# M451_v1 register map
File version: 1.0
Registers are 32-bit, read-write, reset 0x0 unless marked. A register's access mark holds for its fields unless they carry their own. Offsets are from the block's base; [hi:lo] are bit positions; {n}, {i} and the like mark numbered series; 'fields as' and 'values as' point back to an identical list.

## I2C0 — I2C Register Map
Base 0x40080000
Same registers: I2C1 0x40081000
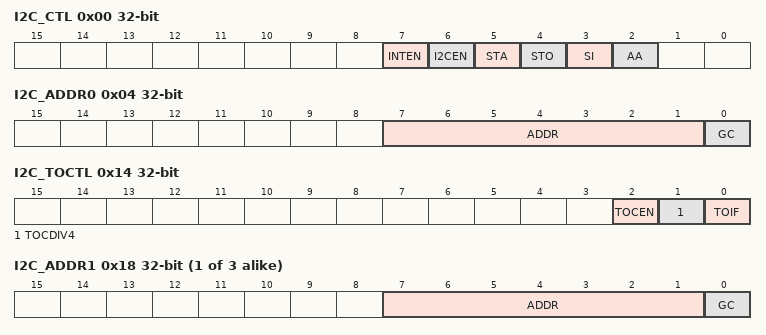
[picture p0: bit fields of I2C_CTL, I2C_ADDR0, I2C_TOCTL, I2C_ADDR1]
0x00 I2C_CTL — I2C Control Register
  [7] INTEN — Enable Interrupt
    0=I2C interrupt Disabled; 1=I2C interrupt Enabled
  [6] I2CEN — I2C Controller Enable Bit
    0=I2C Controller Disabled; 1=I2C Controller Enabled
  [5] STA — I2C START Control. Setting STA to logic 1 to enter Master mode, the I2C hardware sends a START or repeat START condition to bus when the bus is free.
  [4] STO — I2C STOP Control. In Master mode, setting STO to transmit a STOP condition to bus then I2C controller will check the bus condition if a STOP condition is detected. This bit will be cleared by hardware automatically.
  [3] SI — I2C Interrupt Flag. When a new I2C state is present in the I2C_STATUS register, the SI flag is set by hardware. If bit INTEN (I2C_CTL [7]) is set, the I2C interrupt is requested. SI must be cleared by software. Clear SI by writing 1 to this bit. For ACKMEN is set in slave read mode, the SI flag is set in 8th clock period for user to confirm the acknowledge bit and 9th clock period for user to read the data in the data buffer.
  [2] AA — Assert Acknowledge Control
0x04 I2C_ADDR0 — I2C Slave Address Register0
  [7:1] ADDR — I2C Address. The content of this register is irrelevant when I2C is in Master mode. In the slave mode, the seven most significant bits must be loaded with the chip's own address. The I2C hardware will react if either of the address is matched.
  [0] GC — General Call Function
    0=General Call Function Disabled; 1=General Call Function Enabled
0x08 I2C_DAT — I2C Data Register
  [7:0] DAT — I2C Data. Bit [7:0] is located with the 8-bit transferred/received data of I2C serial port.
0x0C I2C_STATUS ro reset 0xF8
  [7:0] STATUS — I2C Status. 2. If the BUSEN and PECEN are enabled, the status of PECERR, I2C_BUSSTS[3], is used to substitute for I2C_STATUS to check the ACK status in the last frame when the byte count done interrupt has active and the PEC frame has been transformed.
0x10 I2C_CLKDIV — I2C Clock Divided Register
  [7:0] DIVIDER — I2C Clock Divided. Note: The minimum value of I2C_CLKDIV is 4.
0x14 I2C_TOCTL — I2C Time-out Control Register
  [2] TOCEN — Time-out Counter Enable Bit. When Enabled, the 14-bit time-out counter will start counting when SI is clear. Setting flag SI to '1' will reset counter and re-start up counting after SI is cleared.
    0=Time-Out Counter Disabled; 1=Time-Out Counter Enabled
  [1] TOCDIV4 — Time-out Counter Input Clock Divided by 4. When Enabled, The time-out period is extend 4 times.
    0=Time-Out Counter Input Clock Divided Disabled; 1=Time-Out Counter Input Clock Divided Enabled
  [0] TOIF — Time-out Flag. This bit is set by hardware when I2C time-out happened and it can interrupt CPU if I2C interrupt enable bit (INTEN) is set to 1. Note: Software can write 1 to clear this bit.
{0x14+4i} I2C_ADDR{i} (i=1..3) — I2C Slave Address Register{i}
  fields as I2C_ADDR0
{0x24+4i} I2C_ADDRMSK{i} (i=0..3) — I2C Slave Address Mask Register{i}
  [7:1] ADDRMSK — I2C Address Mask. I2C bus controllers support multiple address recognition with four address mask register. When the bit in the address mask register is set to one, it means the received corresponding address bit is don't-care. If the bit is set to zero, that means the received corresponding register bit should be exact the same as address register.
    0=Mask Disabled (the received corresponding register bit should be exact the same as address register.); 1=Mask Enabled (the received corresponding address bit is don't care.)
0x3C I2C_WKCTL — I2C Wake-up Control Register
  [0] WKEN — I2C Wake-up Enable Bit
    0=I2C wake-up function Disabled; 1=I2C wake-up function Enabled
0x40 I2C_WKSTS — I2C Wake-up Status Register
  [0] WKIF — I2C Wake-up Flag. When chip is woken up from Power-down mode by I2C, this bit is set to 1. Software can write 1 to clear this bit.
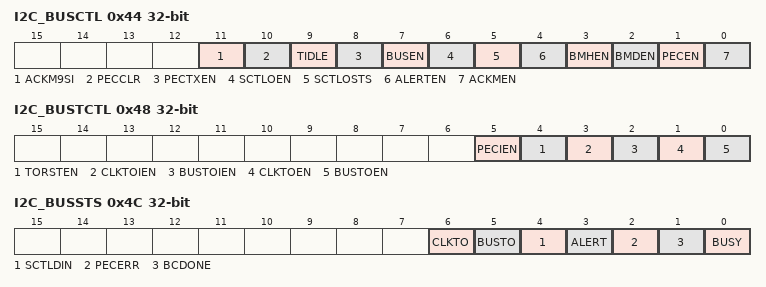
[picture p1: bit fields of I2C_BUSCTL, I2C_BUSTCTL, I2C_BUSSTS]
0x44 I2C_BUSCTL — I2C Bus Management Control Register
  [11] ACKM9SI — Acknowledge Manual Enable Extra SI Interrupt
    0=There is no SI interrupt in the 9th clock cycle when the BUSEN =1 and ACKMEN =1; 1=There is SI interrupt in the 9th clock cycle when the BUSEN =1 and ACKMEN =1
  [10] PECCLR — PEC Clear at Repeat Start. The calculation of PEC starts when PECEN is set to 1 and it is clear when the STA or STO bit is detected. This PECCLR bit is used to enable the condition of REPEAT START can clear the PEC calculation.
    0=The PEC calculation is cleared by 'Repeat Start' function is Disabled; 1=The PEC calculation is cleared by 'Repeat Start' function is Enabled
  [9] TIDLE — Timer Check in Idle State. The BUSTOUT is used to calculate the time-out of clock low in bus active and the idle period in bus Idle. This bit is used to define which condition is enabled. Note: The BUSY (I2C_BUSSTS[0]) indicate the current bus state.
    0=The BUSTOUT is used to calculate the clock low period in bus active; 1=The BUSTOUT is used to calculate the IDLE period in bus Idle
  [8] PECTXEN — Packet Error Checking Byte Transmission/Reception. This bit is set by software, and cleared by hardware when the PEC is transferred, or when a STOP condition or an Address Matched is received
    0=No PEC transfer; 1=PEC transmission/reception is requested
  [7] BUSEN — BUS Enable Bit. Note: When the bit is enabled, the internal 14-bit counter is used to calculate the time out event of clock low condition.
    0=The system management function is Disabled; 1=The system management function is Enable
  [6] SCTLOEN — Suspend or Control Pin Output Enable Bit
    0=The SUSCON pin in input; 1=The output enable is active on the SUSCON pin
  [5] SCTLOSTS — Suspend/Control Data Output Status
    0=The output of SUSCON pin is low; 1=The output of SUSCON pin is high
  [4] ALERTEN — Bus Management Alert Enable Bit
    0=Release the BM_ALERT pin high and Alert Response Header disabled: 0001100x followed by NACK if both of BMDEN and ACKMEN are enabled. BM_ALERT pin not supported; 1=Drive BM_ALERT pin low and Alert Response Address Header enables: 0001100x followed by ACK if both of BMDEN and ACKMEN are enabled. BM_ALERT pin supported
  [3] BMHEN — Bus Management Host Enable Bit
    0=Host function Disabled; 1=Host function Enabled and the SUSCON will be used as CONTROL function
  [2] BMDEN — Bus Management Device Default Address Enable Bit
    0=Device default address Disable. When the address 0'b1100001x coming and the both of BMDEN and ACKMEN are enabled, the device responses NACKed; 1=Device default address Enabled. When the address 0'b1100001x coming and the both of BMDEN and ACKMEN are enabled, the device responses ACKed
  [1] PECEN — Packet Error Checking Calculation Enable Bit
    0=Packet Error Checking Calculation Disabled; 1=Packet Error Checking Calculation Enabled
  [0] ACKMEN — Acknowledge Control by Manual. In order to allow ACK control in slave reception including the command and data, slave byte control mode must be enabled by setting the ACKMEN bit.
    0=Slave byte control Disabled; 1=Slave byte control Enabled. The 9th bit can response the ACK or NACK according the received data by user. When the byte is received, stretching the SCLK signal low between the 8th and 9th SCLK pulse
0x48 I2C_BUSTCTL — I2C Bus Management Timer Control Register
  [5] PECIEN — Packet Error Checking Byte Count Done Interrupt Enable Bit
    0=Indicates the byte count done interrupt is Disabled; 1=Indicates the byte count done interrupt is Enabled
  [4] TORSTEN — Time Out Reset Enable Bit
    0=Indicates the I2C state machine reset is Disable; 1=Indicates the I2C state machine reset is Enable. (The clock and data bus will be released to high)
  [3] CLKTOIEN — Extended Clock Time Out Interrupt Enable Bit
    0=Indicates the time extended interrupt is Disabled; 1=Indicates the time extended interrupt is Enabled
  [2] BUSTOIEN — Time-out Interrupt Enable Bit
    0=Indicates the SCLK low time-out interrupt is Disabled. Indicates the bus IDLE time-out interrupt is Disabled; 1=Indicates the SCLK low time-out interrupt is Enabled. Indicates the bus IDLE time-out interrupt is Enabled
  [1] CLKTOEN — Cumulative Clock Low Time Out Enable Bit. For Master, it calculates the period from START to ACK. For Slave, it calculates the period from START to STOP
    0=Indicates the cumulative clock low time-out detection is Disabled; 1=Indicates the cumulative clock low time-out detection is Enabled
  [0] BUSTOEN — Bus Time Out Enable Bit
    0=Indicates the bus clock low time-out detection is Disabled; 1=Indicates the bus clock low time-out detection is Enabled (bus clock is low for more than TTime-out (in BIDLE=0) or high more than TTime-out(in BIDLE =1)
0x4C I2C_BUSSTS — I2C Bus Management Status Register
  [6] CLKTO — Clock Low Cumulate Time-out Status. Note: Software can write 1 to clear this bit.
    0=Indicates that the cumulative clock low is no any time-out; 1=Indicates that the cumulative clock low time-out occurred
  [5] BUSTO — Bus Time-out Status. In bus busy, the bit indicates the total clock low time-out event occurred otherwise, it indicates the bus idle time-out event occurred. Note: Software can write 1 to clear this bit.
    0=Indicates that there is no any time-out or external clock time-out; 1=Indicates that a time-out or external clock time-out occurred
  [4] SCTLDIN — Bus Suspend or Control Signal Input Status
    0=The input status of SUSCON pin is 0; 1=The input status of SUSCON pin is 1
  [3] ALERT — SMBus Alert Status. Note: 1. The SMALERT pin is an open-drain pin, the pull-high resistor is must in the system. 2. Software can write 1 to clear this bit.
    0=Indicates SMALERT pin state is low. No SMBALERT event; 1=Indicates SMALERT pin state is high. Indicates there is SMBALERT event (falling edge) is detected in SMALERT pin when the BMHEN = 1 (SMBus host configuration) and the ALERTEN = 1
  [2] PECERR — PEC Error in Reception. Note: Software can write 1 to clear this bit.
    0=Indicates the PEC value equal the received PEC data packet; 1=Indicates the PEC value doesn't match the receive PEC data packet
  [1] BCDONE — Byte Count Transmission/Receive Done. Note: Software can write 1 to clear this bit.
    0=Indicates the transmission/ receive is not finished when the PECEN is set; 1=Indicates the transmission/ receive is finished when the PECEN is set
  [0] BUSY — Bus Busy. Indicates that a communication is in progress on the bus. It is set by hardware when a START condition is detected. It is cleared by hardware when a STOP condition is detected
    0=The bus is IDLE (both SCLK and SDA High); 1=The bus is busy
0x50 I2C_PKTSIZE — I2C Packet Error Checking Byte Number Register
  [7:0] PLDSIZE — Transfer Byte Number. The transmission or receive byte number in one transaction when the PECEN is set. The maximum transaction or receive byte is 255 Bytes. Notice: The byte number counting includes address, command code, and data frame.
0x54 I2C_PKTCRC ro — I2C Packet Error Checking Byte Value Register
  [7:0] PECCRC — Packet Error Checking Byte Value
0x58 I2C_BUSTOUT reset 0x5 — I2C Bus Management Timer Register
  [7:0] BUSTO — Bus Management Time-out Value. Indicate the bus time-out value in bus is IDLE or SCLK low. Note: If the user wants to revise the value of BUSTOUT, the TORSTEN (I2C_BUSTCTL[4]) bit shall be set to 1 and clear to 0 first in the BUSEN(I2C_BUSCTL[7]) is set.
0x5C I2C_CLKTOUT reset 0x5 — I2C Bus Management Clock Low Timer Register
  [7:0] CLKTO — Bus Clock Low Timer. The field is used to configure the cumulative clock extension time-out. Note: If the user wants to revise the value of CLKLTOUT, the TORSTEN bit shall be set to 1 and clear to 0 first in the BUSEN is set.
